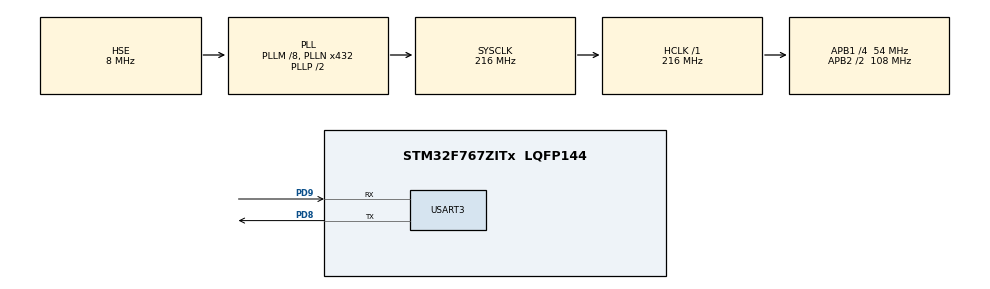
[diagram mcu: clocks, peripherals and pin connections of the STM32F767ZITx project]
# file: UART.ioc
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Dma.Request0=USART3_RX
Dma.Request1=USART3_TX
Dma.USART3_RX.0.Direction=DMA_PERIPH_TO_MEMORY
Dma.USART3_RX.0.FIFOMode=DMA_FIFOMODE_DISABLE
Dma.USART3_RX.0.Instance=DMA1_Stream1
Dma.USART3_RX.0.MemDataAlignment=DMA_MDATAALIGN_BYTE
Dma.USART3_RX.0.MemInc=DMA_MINC_ENABLE
Dma.USART3_RX.0.Mode=DMA_CIRCULAR
Dma.USART3_RX.0.PeriphDataAlignment=DMA_PDATAALIGN_BYTE
Dma.USART3_RX.0.PeriphInc=DMA_PINC_DISABLE
Dma.USART3_RX.0.Priority=DMA_PRIORITY_LOW
Dma.USART3_TX.1.Direction=DMA_MEMORY_TO_PERIPH
Dma.USART3_TX.1.FIFOMode=DMA_FIFOMODE_DISABLE
Dma.USART3_TX.1.Instance=DMA1_Stream3
Dma.USART3_TX.1.MemDataAlignment=DMA_MDATAALIGN_BYTE
Dma.USART3_TX.1.MemInc=DMA_MINC_ENABLE
Dma.USART3_TX.1.Mode=DMA_CIRCULAR
Dma.USART3_TX.1.PeriphDataAlignment=DMA_PDATAALIGN_BYTE
Dma.USART3_TX.1.PeriphInc=DMA_PINC_DISABLE
Dma.USART3_TX.1.Priority=DMA_PRIORITY_LOW
Mcu.Family=STM32F7
Mcu.Name=STM32F767ZITx
Mcu.Package=LQFP144
NVIC.DMA1_Stream1_IRQn=true\:0\:0\:false\:false\:true\:false\:true
NVIC.DMA1_Stream3_IRQn=true\:0\:0\:false\:false\:true\:false\:true
NVIC.PriorityGroup=NVIC_PRIORITYGROUP_4
NVIC.USART3_IRQn=true\:0\:0\:false\:false\:true\:true\:true
PA13.Mode=Serial_Wire
PA13.Signal=SYS_JTMS-SWDIO
PA14.Mode=Serial_Wire
PA14.Signal=SYS_JTCK-SWCLK
PC14/OSC32_IN.Mode=LSE-External-Oscillator
PC14/OSC32_IN.Signal=RCC_OSC32_IN
PC15/OSC32_OUT.Mode=LSE-External-Oscillator
PC15/OSC32_OUT.Signal=RCC_OSC32_OUT
PD8.Mode=Asynchronous
PD8.Signal=USART3_TX
PD9.Mode=Asynchronous
PD9.Signal=USART3_RX
PH0/OSC_IN.Mode=HSE-External-Clock-Source
PH0/OSC_IN.Signal=RCC_OSC_IN
PH1/OSC_OUT.Mode=HSE-External-Clock-Source
PH1/OSC_OUT.Signal=RCC_OSC_OUT
ProjectManager.HeapSize=0x200
ProjectManager.StackSize=0x400
ProjectManager.TargetToolchain=MDK-ARM V5
RCC.AHBFreq_Value=216000000
RCC.APB1CLKDivider=RCC_HCLK_DIV4
RCC.APB1Freq_Value=54000000
RCC.APB1TimFreq_Value=108000000
RCC.APB2CLKDivider=RCC_HCLK_DIV2
RCC.APB2Freq_Value=108000000
RCC.APB2TimFreq_Value=216000000
RCC.CortexFreq_Value=216000000
RCC.HCLKFreq_Value=216000000
RCC.HSE_VALUE=8000000
RCC.HSI_VALUE=16000000
RCC.PLLM=8
RCC.PLLN=432
RCC.PLLSourceVirtual=RCC_PLLSOURCE_HSE
RCC.SYSCLKFreq_VALUE=216000000
RCC.SYSCLKSource=RCC_SYSCLKSOURCE_PLLCLK
RCC.USBFreq_Value=216000000
RCC.VCOOutputFreq_Value=432000000
USART3.VirtualMode-Asynchronous=VM_ASYNC
board=custom

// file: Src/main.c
/* USER CODE BEGIN Header */
/**
  ******************************************************************************
  * @file           : main.c
  * @brief          : Main program body
  ******************************************************************************
  * @attention
  *
  * <h2><center>&copy; Copyright (c) 2019 STMicroelectronics.
  * All rights reserved.</center></h2>
  *
  * This software component is licensed by ST under BSD 3-Clause license,
  * the "License"; You may not use this file except in compliance with the
  * License. You may obtain a copy of the License at:
  *                        opensource.org/licenses/BSD-3-Clause
  *
  ******************************************************************************
  */
/* USER CODE END Header */

#include "main.h"
#include "dma.h"
#include "usart.h"
#include "gpio.h"

/* USER CODE BEGIN PV */
uint8_t send[]="hello world!";
uint8_t get[1];
/* USER CODE END PV */

void SystemClock_Config(void);

int main(void)
{

  /* MCU Configuration--------------------------------------------------------*/

  /* Reset of all peripherals, Initializes the Flash interface and the Systick. */
  HAL_Init();

  /* Configure the system clock */
  SystemClock_Config();

  /* Initialize all configured peripherals */
  MX_GPIO_Init();
  MX_DMA_Init();
  MX_USART3_UART_Init();

  /* Infinite loop */
  while (1)
  {
		HAL_UART_Receive_DMA(&huart3,get,sizeof(get));
		if(get[0]=='a')
			HAL_UART_Transmit_DMA(&huart3,get,sizeof(get));
		if(get[0]=='b')
			HAL_UART_Transmit_DMA(&huart3,(uint8_t *)"test ok",sizeof("test ok"));
  }
}

void SystemClock_Config(void)
{
  RCC_OscInitTypeDef RCC_OscInitStruct = {0};
  RCC_ClkInitTypeDef RCC_ClkInitStruct = {0};
  RCC_PeriphCLKInitTypeDef PeriphClkInitStruct = {0};

  /** Configure the main internal regulator output voltage
  */
  __HAL_RCC_PWR_CLK_ENABLE();
  __HAL_PWR_VOLTAGESCALING_CONFIG(PWR_REGULATOR_VOLTAGE_SCALE1);
  /** Initializes the CPU, AHB and APB busses clocks
  */
  RCC_OscInitStruct.OscillatorType = RCC_OSCILLATORTYPE_HSE;
  RCC_OscInitStruct.HSEState = RCC_HSE_BYPASS;
  RCC_OscInitStruct.PLL.PLLState = RCC_PLL_ON;
  RCC_OscInitStruct.PLL.PLLSource = RCC_PLLSOURCE_HSE;
  RCC_OscInitStruct.PLL.PLLM = 8;
  RCC_OscInitStruct.PLL.PLLN = 432;
  RCC_OscInitStruct.PLL.PLLP = RCC_PLLP_DIV2;
  RCC_OscInitStruct.PLL.PLLQ = 2;
  if (HAL_RCC_OscConfig(&RCC_OscInitStruct) != HAL_OK)
  {
    Error_Handler();
  }
  /** Activate the Over-Drive mode
  */
  if (HAL_PWREx_EnableOverDrive() != HAL_OK)
  {
    Error_Handler();
  }
  /** Initializes the CPU, AHB and APB busses clocks
  */
  RCC_ClkInitStruct.ClockType = RCC_CLOCKTYPE_HCLK|RCC_CLOCKTYPE_SYSCLK
                              |RCC_CLOCKTYPE_PCLK1|RCC_CLOCKTYPE_PCLK2;
  RCC_ClkInitStruct.SYSCLKSource = RCC_SYSCLKSOURCE_PLLCLK;
  RCC_ClkInitStruct.AHBCLKDivider = RCC_SYSCLK_DIV1;
  RCC_ClkInitStruct.APB1CLKDivider = RCC_HCLK_DIV4;
  RCC_ClkInitStruct.APB2CLKDivider = RCC_HCLK_DIV2;

  if (HAL_RCC_ClockConfig(&RCC_ClkInitStruct, FLASH_LATENCY_7) != HAL_OK)
  {
    Error_Handler();
  }
  PeriphClkInitStruct.PeriphClockSelection = RCC_PERIPHCLK_USART3;
  PeriphClkInitStruct.Usart3ClockSelection = RCC_USART3CLKSOURCE_PCLK1;
  if (HAL_RCCEx_PeriphCLKConfig(&PeriphClkInitStruct) != HAL_OK)
  {
    Error_Handler();
  }
}

void Error_Handler(void)
{
}

/************************ (C) COPYRIGHT STMicroelectronics *****END OF FILE****/
